AUTOSAR XML (schema 4-3-0)
standard types defined: uint8, uint16, sint16
package /BMS_VCU_System
  composition sw component type BmsVcuComposition
    component BmsSwc: type=BMS_SWC
    component VcuSwc: type=VCU_SWC
    connect BmsSwc.BMS_StatusPort -> VcuSwc.BMS_StatusPort
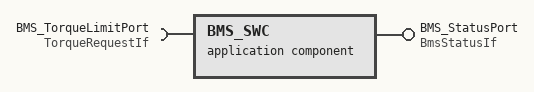
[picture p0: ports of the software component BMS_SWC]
  application sw component type BMS_SWC
    provide port BMS_StatusPort: provided-interface=BmsStatusIf
    require port BMS_TorqueLimitPort: required-interface=TorqueRequestIf
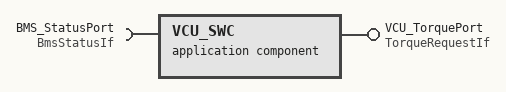
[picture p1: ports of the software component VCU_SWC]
  application sw component type VCU_SWC
    require port BMS_StatusPort: required-interface=BmsStatusIf
    provide port VCU_TorquePort: provided-interface=TorqueRequestIf
package /Interfaces
  sender receiver interface BmsStatusIf
    data StateOfCharge: type=uint8, init-value=0
    data BatteryVoltage: type=uint16, init-value=0
    data BatteryCurrent: type=sint16, init-value=0
  sender receiver interface TorqueRequestIf
    data TorqueRequest: type=uint16, init-value=0
    data VehicleSpeed: type=uint16, init-value=0
